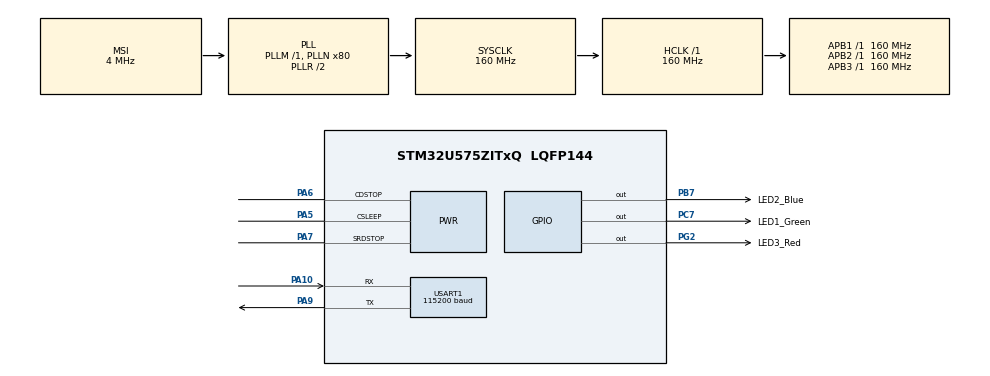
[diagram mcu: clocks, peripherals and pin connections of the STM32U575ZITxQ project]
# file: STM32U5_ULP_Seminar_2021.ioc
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CORTEX_M33_NS.userName=CORTEX_M33
Mcu.Family=STM32U5
Mcu.Name=STM32U575ZITxQ
Mcu.Package=LQFP144
NVIC.PriorityGroup=NVIC_PRIORITYGROUP_4
NVIC.USART1_IRQn=true\:1\:0\:true\:false\:true\:true\:true\:true
PA10.GPIO_PuPd=GPIO_PULLUP
PA10.GPIO_Speed=GPIO_SPEED_FREQ_MEDIUM
PA10.Mode=Asynchronous
PA10.Signal=USART1_RX
PA13\ (JTMS/SWDIO).Mode=Serial_Wire
PA13\ (JTMS/SWDIO).Signal=DEBUG_JTMS-SWDIO
PA14\ (JTCK/SWCLK).Mode=Serial_Wire
PA14\ (JTCK/SWCLK).Signal=DEBUG_JTCK-SWCLK
PA5.Mode=CSLEEP
PA5.Signal=PWR_CSLEEP
PA6.Mode=CDSTOP
PA6.Signal=PWR_CDSTOP
PA7.Mode=SRDSTOP
PA7.Signal=PWR_SRDSTOP
PA9.GPIO_PuPd=GPIO_PULLUP
PA9.GPIO_Speed=GPIO_SPEED_FREQ_MEDIUM
PA9.Mode=Asynchronous
PA9.Signal=USART1_TX
PB7.GPIO_Label=LED2_Blue
PB7.Signal=GPIO_Output
PC7.GPIO_Label=LED1_Green
PC7.Signal=GPIO_Output
PG2.GPIO_Label=LED3_Red
PG2.Signal=GPIO_Output
ProjectManager.HeapSize=0x200
ProjectManager.StackSize=0x400
ProjectManager.TargetToolchain=STM32CubeIDE
RAMCFG.Instance-RAMCFG1_Activate=RAMCFG_SRAM1
RAMCFG.Instance-RAMCFG2_Activate=RAMCFG_SRAM2
RAMCFG.Instance-RAMCFG3_Activate=RAMCFG_SRAM3
RAMCFG.Instance-RAMCFG4_Activate=RAMCFG_SRAM4
RAMCFG.WaitState-RAMCFG1_Activate=RAMCFG_WAITSTATE_1
RAMCFG.WaitState-RAMCFG2_Activate=RAMCFG_WAITSTATE_1
RAMCFG.WaitState-RAMCFG3_Activate=RAMCFG_WAITSTATE_1
RAMCFG.WaitState-RAMCFG4_Activate=RAMCFG_WAITSTATE_1
RCC.ADCFreq_Value=16000000
RCC.AHBFreq_Value=160000000
RCC.APB1Freq_Value=160000000
RCC.APB1TimFreq_Value=160000000
RCC.APB2Freq_Value=160000000
RCC.APB2TimFreq_Value=160000000
RCC.APB3Freq_Value=160000000
RCC.CortexFreq_Value=160000000
RCC.DACCLockSelectionVirtual=RCC_DAC1CLKSOURCE_LSI
RCC.EPOD_VALUE=4000000
RCC.HCLKFreq_Value=160000000
RCC.HSE_VALUE=16000000
RCC.HSI48_VALUE=48000000
RCC.HSI_VALUE=16000000
RCC.LSE_VALUE=32768
RCC.LSIDIV_VALUE=32000
RCC.MSI_VALUE=4000000
RCC.PLLN=80
RCC.SYSCLKFreq_VALUE=160000000
RCC.SYSCLKSource=RCC_SYSCLKSOURCE_PLLCLK
RCC.USART1CLockSelectionVirtual=RCC_USART1CLKSOURCE_HSI
RCC.USBFreq_Value=48000000
RCC.VCOOutputFreq_Value=320000000
USART1.BaudRate=115200
USART1.OverSampling=UART_OVERSAMPLING_8
USART1.VirtualMode-Asynchronous=VM_ASYNC
VP_ICACHE_VS_ICACHE.Mode=DirectMappedCache
VP_PWR_VS_DBSignals.Mode=DisableDeadBatterySignals
VP_PWR_VS_LPOM.Mode=PowerOptimisation
VP_PWR_VS_SECSignals.Mode=Security/Privilege
VP_RAMCFG_VS_RAMCFG1.Mode=RAMCFG1_Activate
VP_RAMCFG_VS_RAMCFG2.Mode=RAMCFG2_Activate
VP_RAMCFG_VS_RAMCFG3.Mode=RAMCFG3_Activate
VP_RAMCFG_VS_RAMCFG4.Mode=RAMCFG4_Activate
VP_RTC_VS_RTC_Activate.Mode=RTC_Enabled
board=custom

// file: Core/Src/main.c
/* USER CODE BEGIN Header */
/**
  ******************************************************************************
  * @file           : main.c
  * @brief          : Main program body
  ******************************************************************************
  * @attention
  *
  * Copyright (c) 2023 STMicroelectronics.
  * All rights reserved.
  *
  * This software is licensed under terms that can be found in the LICENSE file
  * in the root directory of this software component.
  * If no LICENSE file comes with this software, it is provided AS-IS.
  *
  ******************************************************************************
  */
/* USER CODE END Header */
#include "main.h"

RAMCFG_HandleTypeDef hramcfg_SRAM1;
RAMCFG_HandleTypeDef hramcfg_SRAM2;
RAMCFG_HandleTypeDef hramcfg_SRAM3;
RAMCFG_HandleTypeDef hramcfg_SRAM4;

RTC_HandleTypeDef hrtc;

UART_HandleTypeDef huart1;

/* USER CODE BEGIN PV */
bool bCycleTime;
/* USER CODE END PV */

void SystemClock_Config(void);
static void SystemPower_Config(void);
static void MX_GPIO_Init(void);
static void MX_ICACHE_Init(void);
static void MX_USART1_UART_Init(void);
static void MX_RAMCFG_Init(void);
static void MX_RTC_Init(void);

int main(void)
{

  /* MCU Configuration--------------------------------------------------------*/

  /* Reset of all peripherals, Initializes the Flash interface and the Systick. */
  HAL_Init();

  /* Configure the system clock */
  SystemClock_Config();

  /* Configure the System Power */
  SystemPower_Config();

  /* Initialize all configured peripherals */
  MX_GPIO_Init();
  MX_ICACHE_Init();
  MX_USART1_UART_Init();
  MX_RAMCFG_Init();
  MX_RTC_Init();
  /* USER CODE BEGIN 2 */
  /* Toggle ALl three LEDs for 3 seconds */
  for (int loop = 0; loop < 10; loop++)
  {
	  HAL_GPIO_TogglePin(LED3_Red_GPIO_Port, LED3_Red_Pin);
	  HAL_Delay(100);
	  HAL_GPIO_TogglePin(LED2_Blue_GPIO_Port, LED2_Blue_Pin);
	  HAL_Delay(100);
	  HAL_GPIO_TogglePin(LED1_Green_GPIO_Port, LED1_Green_Pin);
	  HAL_Delay(100);
  }

   /* Leave Blue LED2 On until entering Lower Power Mode */
   HAL_GPIO_WritePin(LED2_Blue_GPIO_Port, LED2_Blue_Pin,GPIO_PIN_SET);

  /* USER CODE END 2 */

  /* Infinite loop */
  while (1)
  {

    /* USER CODE BEGIN 3 */
	  __WFI();
	  if (bCycleTime)
	  {
		  HAL_GPIO_TogglePin(LED3_Red_GPIO_Port, LED3_Red_Pin);
		  bCycleTime = false;
	  }
  }
  /* USER CODE END 3 */
}

void SystemClock_Config(void)
{
  RCC_OscInitTypeDef RCC_OscInitStruct = {0};
  RCC_ClkInitTypeDef RCC_ClkInitStruct = {0};

  /** Configure the main internal regulator output voltage
  */
  if (HAL_PWREx_ControlVoltageScaling(PWR_REGULATOR_VOLTAGE_SCALE1) != HAL_OK)
  {
    Error_Handler();
  }

  /** Initializes the CPU, AHB and APB buses clocks
  */
  RCC_OscInitStruct.OscillatorType = RCC_OSCILLATORTYPE_HSI|RCC_OSCILLATORTYPE_LSI
                              |RCC_OSCILLATORTYPE_MSI;
  RCC_OscInitStruct.HSIState = RCC_HSI_ON;
  RCC_OscInitStruct.HSICalibrationValue = RCC_HSICALIBRATION_DEFAULT;
  RCC_OscInitStruct.LSIState = RCC_LSI_ON;
  RCC_OscInitStruct.MSIState = RCC_MSI_ON;
  RCC_OscInitStruct.MSICalibrationValue = RCC_MSICALIBRATION_DEFAULT;
  RCC_OscInitStruct.MSIClockRange = RCC_MSIRANGE_4;
  RCC_OscInitStruct.LSIDiv = RCC_LSI_DIV1;
  RCC_OscInitStruct.PLL.PLLState = RCC_PLL_ON;
  RCC_OscInitStruct.PLL.PLLSource = RCC_PLLSOURCE_MSI;
  RCC_OscInitStruct.PLL.PLLMBOOST = RCC_PLLMBOOST_DIV1;
  RCC_OscInitStruct.PLL.PLLM = 1;
  RCC_OscInitStruct.PLL.PLLN = 80;
  RCC_OscInitStruct.PLL.PLLP = 2;
  RCC_OscInitStruct.PLL.PLLQ = 2;
  RCC_OscInitStruct.PLL.PLLR = 2;
  RCC_OscInitStruct.PLL.PLLRGE = RCC_PLLVCIRANGE_0;
  RCC_OscInitStruct.PLL.PLLFRACN = 0;
  if (HAL_RCC_OscConfig(&RCC_OscInitStruct) != HAL_OK)
  {
    Error_Handler();
  }

  /** Initializes the CPU, AHB and APB buses clocks
  */
  RCC_ClkInitStruct.ClockType = RCC_CLOCKTYPE_HCLK|RCC_CLOCKTYPE_SYSCLK
                              |RCC_CLOCKTYPE_PCLK1|RCC_CLOCKTYPE_PCLK2
                              |RCC_CLOCKTYPE_PCLK3;
  RCC_ClkInitStruct.SYSCLKSource = RCC_SYSCLKSOURCE_PLLCLK;
  RCC_ClkInitStruct.AHBCLKDivider = RCC_SYSCLK_DIV1;
  RCC_ClkInitStruct.APB1CLKDivider = RCC_HCLK_DIV1;
  RCC_ClkInitStruct.APB2CLKDivider = RCC_HCLK_DIV1;
  RCC_ClkInitStruct.APB3CLKDivider = RCC_HCLK_DIV1;

  if (HAL_RCC_ClockConfig(&RCC_ClkInitStruct, FLASH_LATENCY_4) != HAL_OK)
  {
    Error_Handler();
  }
}

/**
  * @brief Power Configuration
  * @retval None
  */
static void SystemPower_Config(void)
{
  HAL_PWREx_EnableVddIO2();

  /*
   * Disable the internal Pull-Up in Dead Battery pins of UCPD peripheral
   */
  HAL_PWREx_DisableUCPDDeadBattery();
}

static void MX_ICACHE_Init(void)
{

  /** Enable instruction cache in 1-way (direct mapped cache)
  */
  if (HAL_ICACHE_ConfigAssociativityMode(ICACHE_1WAY) != HAL_OK)
  {
    Error_Handler();
  }
  if (HAL_ICACHE_Enable() != HAL_OK)
  {
    Error_Handler();
  }

}

static void MX_RAMCFG_Init(void)
{

  /** Initialize RAMCFG SRAM1
  */
  hramcfg_SRAM1.Instance = RAMCFG_SRAM1;
  if (HAL_RAMCFG_Init(&hramcfg_SRAM1) != HAL_OK)
  {
    Error_Handler();
  }
  if (HAL_RAMCFG_ConfigWaitState(&hramcfg_SRAM1, RAMCFG_WAITSTATE_1) != HAL_OK)
  {
    Error_Handler();
  }

  /** Initialize RAMCFG SRAM2
  */
  hramcfg_SRAM2.Instance = RAMCFG_SRAM2;
  if (HAL_RAMCFG_Init(&hramcfg_SRAM2) != HAL_OK)
  {
    Error_Handler();
  }
  if (HAL_RAMCFG_ConfigWaitState(&hramcfg_SRAM2, RAMCFG_WAITSTATE_1) != HAL_OK)
  {
    Error_Handler();
  }

  /** Initialize RAMCFG SRAM3
  */
  hramcfg_SRAM3.Instance = RAMCFG_SRAM3;
  if (HAL_RAMCFG_Init(&hramcfg_SRAM3) != HAL_OK)
  {
    Error_Handler();
  }
  if (HAL_RAMCFG_ConfigWaitState(&hramcfg_SRAM3, RAMCFG_WAITSTATE_1) != HAL_OK)
  {
    Error_Handler();
  }

  /** Initialize RAMCFG SRAM4
  */
  hramcfg_SRAM4.Instance = RAMCFG_SRAM4;
  if (HAL_RAMCFG_Init(&hramcfg_SRAM4) != HAL_OK)
  {
    Error_Handler();
  }
  if (HAL_RAMCFG_ConfigWaitState(&hramcfg_SRAM4, RAMCFG_WAITSTATE_1) != HAL_OK)
  {
    Error_Handler();
  }

}

static void MX_RTC_Init(void)
{

  RTC_PrivilegeStateTypeDef privilegeState = {0};

  /** Initialize RTC Only
  */
  hrtc.Instance = RTC;
  hrtc.Init.HourFormat = RTC_HOURFORMAT_24;
  hrtc.Init.AsynchPrediv = 127;
  hrtc.Init.SynchPrediv = 255;
  hrtc.Init.OutPut = RTC_OUTPUT_DISABLE;
  hrtc.Init.OutPutRemap = RTC_OUTPUT_REMAP_NONE;
  hrtc.Init.OutPutPolarity = RTC_OUTPUT_POLARITY_HIGH;
  hrtc.Init.OutPutType = RTC_OUTPUT_TYPE_OPENDRAIN;
  hrtc.Init.OutPutPullUp = RTC_OUTPUT_PULLUP_NONE;
  hrtc.Init.BinMode = RTC_BINARY_NONE;
  if (HAL_RTC_Init(&hrtc) != HAL_OK)
  {
    Error_Handler();
  }
  privilegeState.rtcPrivilegeFull = RTC_PRIVILEGE_FULL_NO;
  privilegeState.backupRegisterPrivZone = RTC_PRIVILEGE_BKUP_ZONE_NONE;
  privilegeState.backupRegisterStartZone2 = RTC_BKP_DR0;
  privilegeState.backupRegisterStartZone3 = RTC_BKP_DR0;
  if (HAL_RTCEx_PrivilegeModeSet(&hrtc, &privilegeState) != HAL_OK)
  {
    Error_Handler();
  }

}

static void MX_USART1_UART_Init(void)
{

  huart1.Instance = USART1;
  huart1.Init.BaudRate = 115200;
  huart1.Init.WordLength = UART_WORDLENGTH_8B;
  huart1.Init.StopBits = UART_STOPBITS_1;
  huart1.Init.Parity = UART_PARITY_NONE;
  huart1.Init.Mode = UART_MODE_TX_RX;
  huart1.Init.HwFlowCtl = UART_HWCONTROL_NONE;
  huart1.Init.OverSampling = UART_OVERSAMPLING_8;
  huart1.Init.OneBitSampling = UART_ONE_BIT_SAMPLE_DISABLE;
  huart1.Init.ClockPrescaler = UART_PRESCALER_DIV1;
  huart1.AdvancedInit.AdvFeatureInit = UART_ADVFEATURE_NO_INIT;
  if (HAL_UART_Init(&huart1) != HAL_OK)
  {
    Error_Handler();
  }
  if (HAL_UARTEx_SetTxFifoThreshold(&huart1, UART_TXFIFO_THRESHOLD_1_8) != HAL_OK)
  {
    Error_Handler();
  }
  if (HAL_UARTEx_SetRxFifoThreshold(&huart1, UART_RXFIFO_THRESHOLD_1_8) != HAL_OK)
  {
    Error_Handler();
  }
  if (HAL_UARTEx_DisableFifoMode(&huart1) != HAL_OK)
  {
    Error_Handler();
  }

}

static void MX_GPIO_Init(void)
{
  GPIO_InitTypeDef GPIO_InitStruct = {0};

  /* GPIO Ports Clock Enable */
  __HAL_RCC_GPIOA_CLK_ENABLE();
  __HAL_RCC_GPIOG_CLK_ENABLE();
  __HAL_RCC_GPIOC_CLK_ENABLE();
  __HAL_RCC_GPIOB_CLK_ENABLE();

  /*Configure GPIO pin Output Level */
  HAL_GPIO_WritePin(LED3_Red_GPIO_Port, LED3_Red_Pin, GPIO_PIN_RESET);

  /*Configure GPIO pin Output Level */
  HAL_GPIO_WritePin(LED1_Green_GPIO_Port, LED1_Green_Pin, GPIO_PIN_RESET);

  /*Configure GPIO pin Output Level */
  HAL_GPIO_WritePin(LED2_Blue_GPIO_Port, LED2_Blue_Pin, GPIO_PIN_RESET);

  /*Configure GPIO pin : PA5 */
  GPIO_InitStruct.Pin = GPIO_PIN_5;
  GPIO_InitStruct.Mode = GPIO_MODE_AF_PP;
  GPIO_InitStruct.Pull = GPIO_NOPULL;
  GPIO_InitStruct.Speed = GPIO_SPEED_FREQ_LOW;
  GPIO_InitStruct.Alternate = GPIO_AF0_CSLEEP;
  HAL_GPIO_Init(GPIOA, &GPIO_InitStruct);

  /*Configure GPIO pin : PA6 */
  GPIO_InitStruct.Pin = GPIO_PIN_6;
  GPIO_InitStruct.Mode = GPIO_MODE_AF_PP;
  GPIO_InitStruct.Pull = GPIO_NOPULL;
  GPIO_InitStruct.Speed = GPIO_SPEED_FREQ_LOW;
  GPIO_InitStruct.Alternate = GPIO_AF0_CSTOP;
  HAL_GPIO_Init(GPIOA, &GPIO_InitStruct);

  /*Configure GPIO pin : PA7 */
  GPIO_InitStruct.Pin = GPIO_PIN_7;
  GPIO_InitStruct.Mode = GPIO_MODE_AF_PP;
  GPIO_InitStruct.Pull = GPIO_NOPULL;
  GPIO_InitStruct.Speed = GPIO_SPEED_FREQ_LOW;
  GPIO_InitStruct.Alternate = GPIO_AF0_SRDSTOP;
  HAL_GPIO_Init(GPIOA, &GPIO_InitStruct);

  /*Configure GPIO pin : LED3_Red_Pin */
  GPIO_InitStruct.Pin = LED3_Red_Pin;
  GPIO_InitStruct.Mode = GPIO_MODE_OUTPUT_PP;
  GPIO_InitStruct.Pull = GPIO_NOPULL;
  GPIO_InitStruct.Speed = GPIO_SPEED_FREQ_LOW;
  HAL_GPIO_Init(LED3_Red_GPIO_Port, &GPIO_InitStruct);

  /*Configure GPIO pin : LED1_Green_Pin */
  GPIO_InitStruct.Pin = LED1_Green_Pin;
  GPIO_InitStruct.Mode = GPIO_MODE_OUTPUT_PP;
  GPIO_InitStruct.Pull = GPIO_NOPULL;
  GPIO_InitStruct.Speed = GPIO_SPEED_FREQ_LOW;
  HAL_GPIO_Init(LED1_Green_GPIO_Port, &GPIO_InitStruct);

  /*Configure GPIO pin : LED2_Blue_Pin */
  GPIO_InitStruct.Pin = LED2_Blue_Pin;
  GPIO_InitStruct.Mode = GPIO_MODE_OUTPUT_PP;
  GPIO_InitStruct.Pull = GPIO_NOPULL;
  GPIO_InitStruct.Speed = GPIO_SPEED_FREQ_LOW;
  HAL_GPIO_Init(LED2_Blue_GPIO_Port, &GPIO_InitStruct);

}

void Error_Handler(void)
{
  __disable_irq();
  while (1)
  {
  }
}
